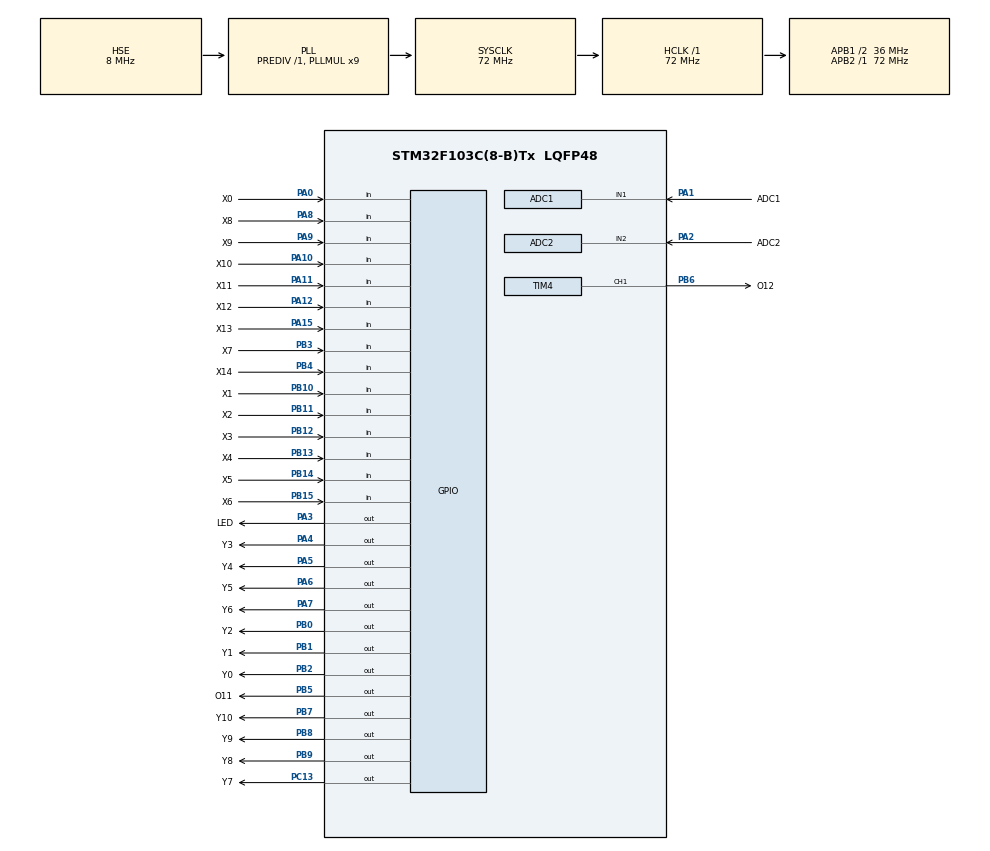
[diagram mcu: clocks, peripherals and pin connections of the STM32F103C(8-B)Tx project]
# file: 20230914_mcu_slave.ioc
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ADC1.Channel-0\#ChannelRegularConversion=ADC_CHANNEL_1
ADC1.NbrOfConversionFlag=1
ADC1.Rank-0\#ChannelRegularConversion=1
ADC1.SamplingTime-0\#ChannelRegularConversion=ADC_SAMPLETIME_1CYCLE_5
ADC1.master=1
ADC2.Channel-0\#ChannelRegularConversion=ADC_CHANNEL_2
ADC2.Rank-0\#ChannelRegularConversion=1
ADC2.SamplingTime-0\#ChannelRegularConversion=ADC_SAMPLETIME_1CYCLE_5
Mcu.Family=STM32F1
Mcu.Name=STM32F103C(8-B)Tx
Mcu.Package=LQFP48
NVIC.PriorityGroup=NVIC_PRIORITYGROUP_4
PA0-WKUP.GPIO_Label=X0
PA0-WKUP.GPIO_PuPd=GPIO_NOPULL
PA0-WKUP.Signal=GPIO_Input
PA1.GPIO_Label=ADC1
PA1.Signal=ADCx_IN1
PA10.GPIO_Label=X10
PA10.Signal=GPIO_Input
PA11.GPIO_Label=X11
PA11.Signal=GPIO_Input
PA12.GPIO_Label=X12
PA12.Signal=GPIO_Input
PA13.Mode=Serial_Wire
PA13.Signal=SYS_JTMS-SWDIO
PA14.Mode=Serial_Wire
PA14.Signal=SYS_JTCK-SWCLK
PA15.GPIO_Label=X13
PA15.Signal=GPIO_Input
PA2.GPIO_Label=ADC2
PA2.Signal=ADCx_IN2
PA3.GPIO_Label=LED
PA3.PinState=GPIO_PIN_RESET
PA3.Signal=GPIO_Output
PA4.GPIO_Label=Y3
PA4.PinState=GPIO_PIN_RESET
PA4.Signal=GPIO_Output
PA5.GPIO_Label=Y4
PA5.PinState=GPIO_PIN_RESET
PA5.Signal=GPIO_Output
PA6.GPIO_Label=Y5
PA6.PinState=GPIO_PIN_RESET
PA6.Signal=GPIO_Output
PA7.GPIO_Label=Y6
PA7.PinState=GPIO_PIN_RESET
PA7.Signal=GPIO_Output
PA8.GPIO_Label=X8
PA8.Signal=GPIO_Input
PA9.GPIO_Label=X9
PA9.Signal=GPIO_Input
PB0.GPIO_Label=Y2
PB0.PinState=GPIO_PIN_RESET
PB0.Signal=GPIO_Output
PB1.GPIO_Label=Y1
PB1.PinState=GPIO_PIN_RESET
PB1.Signal=GPIO_Output
PB10.GPIO_Label=X1
PB10.GPIO_PuPd=GPIO_PULLUP
PB10.Signal=GPIO_Input
PB11.GPIO_Label=X2
PB11.Signal=GPIO_Input
PB12.GPIO_Label=X3
PB12.Signal=GPIO_Input
PB13.GPIO_Label=X4
PB13.Signal=GPIO_Input
PB14.GPIO_Label=X5
PB14.Signal=GPIO_Input
PB15.GPIO_Label=X6
PB15.Signal=GPIO_Input
PB2.GPIO_Label=Y0
PB2.PinState=GPIO_PIN_RESET
PB2.Signal=GPIO_Output
PB3.GPIO_Label=X7
PB3.GPIO_PuPd=GPIO_NOPULL
PB3.Signal=GPIO_Input
PB4.GPIO_Label=X14
PB4.Signal=GPIO_Input
PB5.GPIO_Label=O11
PB5.GPIO_Speed=GPIO_SPEED_FREQ_LOW
PB5.PinState=GPIO_PIN_SET
PB5.Signal=GPIO_Output
PB6.GPIO_Label=O12
PB6.Signal=S_TIM4_CH1
PB7.GPIO_Label=Y10
PB7.PinState=GPIO_PIN_RESET
PB7.Signal=GPIO_Output
PB8.GPIO_Label=Y9
PB8.PinState=GPIO_PIN_RESET
PB8.Signal=GPIO_Output
PB9.GPIO_Label=Y8
PB9.PinState=GPIO_PIN_RESET
PB9.Signal=GPIO_Output
PC13-TAMPER-RTC.GPIO_Label=Y7
PC13-TAMPER-RTC.PinState=GPIO_PIN_RESET
PC13-TAMPER-RTC.Signal=GPIO_Output
PD0-OSC_IN.Mode=HSE-External-Oscillator
PD0-OSC_IN.Signal=RCC_OSC_IN
PD1-OSC_OUT.Mode=HSE-External-Oscillator
PD1-OSC_OUT.Signal=RCC_OSC_OUT
ProjectManager.HeapSize=0x200
ProjectManager.StackSize=0x400
ProjectManager.TargetToolchain=EWARM V8.32
RCC.ADCPresc=RCC_ADCPCLK2_DIV6
RCC.AHBFreq_Value=72000000
RCC.APB1CLKDivider=RCC_HCLK_DIV2
RCC.APB1Freq_Value=36000000
RCC.APB1TimFreq_Value=72000000
RCC.APB2Freq_Value=72000000
RCC.APB2TimFreq_Value=72000000
RCC.HCLKFreq_Value=72000000
RCC.PLLMUL=RCC_PLL_MUL9
RCC.PLLSourceVirtual=RCC_PLLSOURCE_HSE
RCC.SYSCLKFreq_VALUE=72000000
RCC.SYSCLKSource=RCC_SYSCLKSOURCE_PLLCLK
RCC.USBFreq_Value=72000000
SH.ADCx_IN1.0=ADC1_IN1,IN1
SH.ADCx_IN2.0=ADC2_IN2,IN2
SH.ADCx_IN2.1=ADC1_IN2,IN2
SH.S_TIM4_CH1.0=TIM4_CH1,PWM Generation1 CH1
TIM4.AutoReloadPreload=TIM_AUTORELOAD_PRELOAD_ENABLE
TIM4.Channel-PWM\ Generation1\ CH1=TIM_CHANNEL_1
TIM4.OCPolarity_1=TIM_OCPOLARITY_LOW
TIM4.Period=1000-1
TIM4.Prescaler=72-1
VP_TIM4_VS_ClockSourceINT.Mode=Internal
board=custom

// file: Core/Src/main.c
/* USER CODE BEGIN Header */
/**
 ******************************************************************************
 * @file           : main.c
 * @brief          : Main program body
 ******************************************************************************
 * @attention
 *
 * Copyright (c) 2023 STMicroelectronics.
 * All rights reserved.
 *
 * This software is licensed under terms that can be found in the LICENSE file
 * in the root directory of this software component.
 * If no LICENSE file comes with this software, it is provided AS-IS.
 *
 ******************************************************************************
 */
/* USER CODE END Header */
#include "main.h"
#include "adc.h"
#include "tim.h"
#include "gpio.h"

/* USER CODE BEGIN PV */

systemParam_t g_sysRam; /*!< 全局运行数据 */
/* USER CODE END PV */

void SystemClock_Config(void);

/* USER CODE BEGIN 0 */
extern void task_1ms();
/* USER CODE END 0 */

int main(void)
{

  /* MCU Configuration--------------------------------------------------------*/

  /* Reset of all peripherals, Initializes the Flash interface and the Systick. */
  HAL_Init();

  /* Configure the system clock */
  SystemClock_Config();

  /* Initialize all configured peripherals */
  MX_GPIO_Init();
  MX_ADC1_Init();
  MX_ADC2_Init();
  MX_TIM4_Init();

  /* Infinite loop */
  /* USER CODE BEGIN WHILE */
  while (1)
  {
    task_1ms();
    /* USER CODE END WHILE */

  }
}

void SystemClock_Config(void)
{
  RCC_OscInitTypeDef RCC_OscInitStruct = {0};
  RCC_ClkInitTypeDef RCC_ClkInitStruct = {0};
  RCC_PeriphCLKInitTypeDef PeriphClkInit = {0};

  /** Initializes the RCC Oscillators according to the specified parameters
  * in the RCC_OscInitTypeDef structure.
  */
  RCC_OscInitStruct.OscillatorType = RCC_OSCILLATORTYPE_HSE;
  RCC_OscInitStruct.HSEState = RCC_HSE_ON;
  RCC_OscInitStruct.HSEPredivValue = RCC_HSE_PREDIV_DIV1;
  RCC_OscInitStruct.HSIState = RCC_HSI_ON;
  RCC_OscInitStruct.PLL.PLLState = RCC_PLL_ON;
  RCC_OscInitStruct.PLL.PLLSource = RCC_PLLSOURCE_HSE;
  RCC_OscInitStruct.PLL.PLLMUL = RCC_PLL_MUL9;
  if (HAL_RCC_OscConfig(&RCC_OscInitStruct) != HAL_OK)
  {
    Error_Handler();
  }

  /** Initializes the CPU, AHB and APB buses clocks
  */
  RCC_ClkInitStruct.ClockType = RCC_CLOCKTYPE_HCLK|RCC_CLOCKTYPE_SYSCLK
                              |RCC_CLOCKTYPE_PCLK1|RCC_CLOCKTYPE_PCLK2;
  RCC_ClkInitStruct.SYSCLKSource = RCC_SYSCLKSOURCE_PLLCLK;
  RCC_ClkInitStruct.AHBCLKDivider = RCC_SYSCLK_DIV1;
  RCC_ClkInitStruct.APB1CLKDivider = RCC_HCLK_DIV2;
  RCC_ClkInitStruct.APB2CLKDivider = RCC_HCLK_DIV1;

  if (HAL_RCC_ClockConfig(&RCC_ClkInitStruct, FLASH_LATENCY_2) != HAL_OK)
  {
    Error_Handler();
  }
  PeriphClkInit.PeriphClockSelection = RCC_PERIPHCLK_ADC;
  PeriphClkInit.AdcClockSelection = RCC_ADCPCLK2_DIV6;
  if (HAL_RCCEx_PeriphCLKConfig(&PeriphClkInit) != HAL_OK)
  {
    Error_Handler();
  }
}

void Error_Handler(void)
{
  __disable_irq();
  while (1)
  {
  }
}
